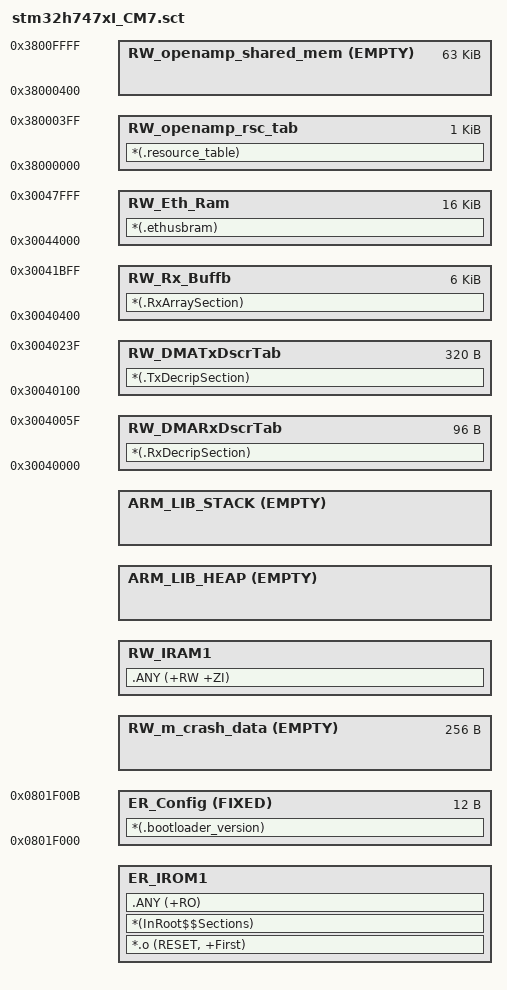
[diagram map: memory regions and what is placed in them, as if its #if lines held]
#! armcc -E
; Scatter-Loading Description File
;
; SPDX-License-Identifier: BSD-3-Clause
;******************************************************************************
;* @attention
;*
;* Copyright (c) 2016-2020 STMicroelectronics.
;* All rights reserved.
;*
;* This software component is licensed by ST under BSD 3-Clause license,
;* the "License"; You may not use this file except in compliance with the
;* License. You may obtain a copy of the License at:
;*                        opensource.org/licenses/BSD-3-Clause
;*
;******************************************************************************

#include "../cmsis_nvic.h"

#if !defined(MBED_APP_START)
  #define MBED_APP_START  MBED_ROM_START
#endif

#if !defined(MBED_APP_SIZE)
  #define MBED_APP_SIZE  MBED_ROM_SIZE
#endif

#if !defined(MBED_CONF_TARGET_BOOT_STACK_SIZE)
/* This value is normally defined by the tools to 0x1000 for bare metal and 0x400 for RTOS */
#if defined(MBED_BOOT_STACK_SIZE)
#define MBED_CONF_TARGET_BOOT_STACK_SIZE MBED_BOOT_STACK_SIZE
#else
#define MBED_CONF_TARGET_BOOT_STACK_SIZE 0x400
#endif
#endif

#define MBED_VECTTABLE_RAM_START    (NVIC_RAM_VECTOR_ADDRESS)
#define MBED_VECTTABLE_RAM_SIZE     (((NVIC_NUM_VECTORS * 4) + 7) AND ~7)

#define MBED_CRASH_REPORT_RAM_START (MBED_VECTTABLE_RAM_START + MBED_VECTTABLE_RAM_SIZE)
#define MBED_CRASH_REPORT_RAM_SIZE  0x100

#define __OPENAMP_region_start__  = 0x38000400
#define __OPENAMP_region_end__ = 0x38010000

#define _ConfigStart = 0x0801F000;

LR_IROM1  MBED_APP_START  MBED_APP_SIZE  {

  ER_IROM1  MBED_APP_START  MBED_APP_SIZE  {
    *.o (RESET, +First)
    *(InRoot$$Sections)
    .ANY (+RO)
  }
  
  ER_Config 0x0801F000 FIXED 0xC { ; load address = execution address
    *(.bootloader_version)
  }

  RW_m_crash_data MBED_CRASH_REPORT_RAM_START EMPTY MBED_CRASH_REPORT_RAM_SIZE { ; RW data
  }

  RW_IRAM1  (MBED_RAM_START)  {  ; RW data
    .ANY (+RW +ZI)
  }

  ARM_LIB_HEAP  AlignExpr(+0, 16)  EMPTY  (MBED_RAM_START + MBED_RAM_SIZE - MBED_CONF_TARGET_BOOT_STACK_SIZE - AlignExpr(ImageLimit(RW_IRAM1), 16))  { ; Heap growing up
  }

  ARM_LIB_STACK  (MBED_RAM_START + MBED_RAM_SIZE)  EMPTY  -MBED_CONF_TARGET_BOOT_STACK_SIZE  { ; Stack region growing down
  }

  RW_openamp_rsc_tab 0x38000000 0x400 {
    *(.resource_table)
  }

  RW_openamp_shared_mem 0x38000400 EMPTY 0xFC00 {
  }

  RW_DMARxDscrTab 0x30040000 0x60 {
    *(.RxDecripSection)
  }
  RW_DMATxDscrTab 0x30040100 0x140 {
    *(.TxDecripSection)
  }
  RW_Rx_Buffb 0x30040400 0x1800 {
    *(.RxArraySection)
  }
  RW_Eth_Ram 0x30044000 0x4000 {
    *(.ethusbram)
  }

}
